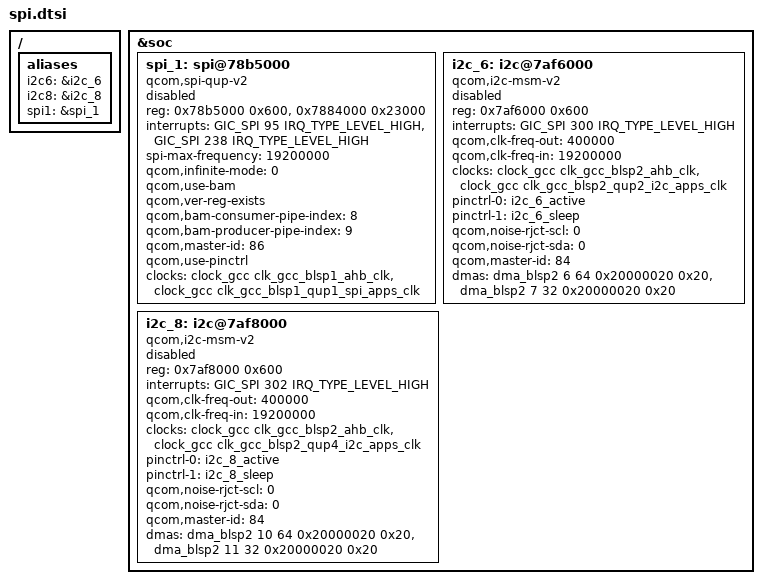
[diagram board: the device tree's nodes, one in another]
/ {
	aliases {
		i2c6 = &i2c_6;
		i2c8 = &i2c_8;
		spi1 = &spi_1;
	};
};

&soc {
	spi_1: spi@78b5000 { /* BLSP1 QUP1 */
		compatible = "qcom,spi-qup-v2";
		#address-cells = <1>;
		#size-cells = <0>;
		reg-names = "spi_physical", "spi_bam_physical";
		reg = <0x78b5000 0x600>, 
				<0x7884000 0x23000>;
		interrupt-names = "spi_irq", "spi_bam_irq";
		interrupts = <GIC_SPI 95 IRQ_TYPE_LEVEL_HIGH>,
				<GIC_SPI 238 IRQ_TYPE_LEVEL_HIGH>;
		spi-max-frequency = <19200000>;
		qcom,infinite-mode = <0>;
		qcom,use-bam;
		qcom,ver-reg-exists;
		qcom,bam-consumer-pipe-index = <8>;
		qcom,bam-producer-pipe-index = <9>;
		qcom,master-id = <86>;
		qcom,use-pinctrl;
		clock-names = "iface_clk", "core_clk";
		clocks = <&clock_gcc clk_gcc_blsp1_ahb_clk>,
					<&clock_gcc clk_gcc_blsp1_qup1_spi_apps_clk>;
		status = "disabled";
	};

	i2c_6: i2c@7af6000 { /* BLSP2 QUP2 */
		compatible = "qcom,i2c-msm-v2";
		#address-cells = <1>;
		#size-cells = <0>;
		reg-names = "qup_phys_addr";
		reg = <0x7af6000 0x600>;
		interrupt-names = "qup_irq";
		interrupts = <GIC_SPI 300 IRQ_TYPE_LEVEL_HIGH>;
		qcom,clk-freq-out = <400000>;
		qcom,clk-freq-in = <19200000>;
		clock-names = "iface_clk", "core_clk";
		clocks = <&clock_gcc clk_gcc_blsp2_ahb_clk>,
					<&clock_gcc clk_gcc_blsp2_qup2_i2c_apps_clk>;
		pinctrl-names = "i2c_active", "i2c_sleep";
		pinctrl-0 = <&i2c_6_active>;
		pinctrl-1 = <&i2c_6_sleep>;
		qcom,noise-rjct-scl = <0>;
		qcom,noise-rjct-sda = <0>;
		qcom,master-id = <84>;
		dmas = <&dma_blsp2 6 64 0x20000020 0x20>, 
				<&dma_blsp2 7 32 0x20000020 0x20>;
		dma-names = "tx", "rx";
		status = "disabled";
	};

	i2c_8: i2c@7af8000 { /* BLSP2 QUP4 */
		compatible = "qcom,i2c-msm-v2";
		#address-cells = <1>;
		#size-cells = <0>;
		reg-names = "qup_phys_addr";
		reg = <0x7af8000 0x600>;
		interrupt-names = "qup_irq";
		interrupts = <GIC_SPI 302 IRQ_TYPE_LEVEL_HIGH>;
		qcom,clk-freq-out = <400000>;
		qcom,clk-freq-in = <19200000>;
		clock-names = "iface_clk", "core_clk";
		clocks = <&clock_gcc clk_gcc_blsp2_ahb_clk>, 
					<&clock_gcc clk_gcc_blsp2_qup4_i2c_apps_clk>;
		pinctrl-names = "i2c_active", "i2c_sleep";
		pinctrl-0 = <&i2c_8_active>;
		pinctrl-1 = <&i2c_8_sleep>;
		qcom,noise-rjct-scl = <0>;
		qcom,noise-rjct-sda = <0>;
		qcom,master-id = <84>;
		dmas = <&dma_blsp2 10 64 0x20000020 0x20>, 
				<&dma_blsp2 11 32 0x20000020 0x20>;
		dma-names = "tx", "rx";
		status = "disabled";
	};
};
